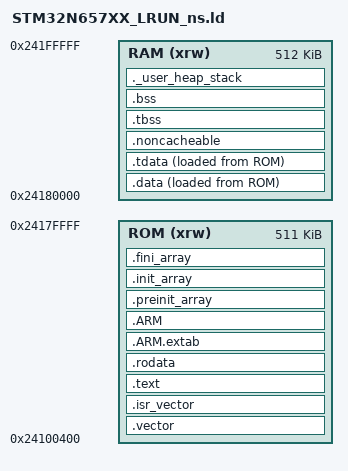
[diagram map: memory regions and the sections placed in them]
/*
 *  STM32N657XX LRUN (Non-secure) linker script for TOPPERS/ASP
 *  Based on STM32Cube STM32N657XX_LRUN_ns.ld (H747 版と同様に .vector を先頭配置)
 */

ENTRY(Reset_Handler)

software_init_hook = 0;

MEMORY
{
  ROM    (xrw)    : ORIGIN = 0x24100400,   LENGTH = 511K
  RAM    (xrw)    : ORIGIN = 0x24180000,   LENGTH = 512K
}

_estack = ORIGIN(RAM) + LENGTH(RAM);
_sstack = _estack - _Min_Stack_Size;

_Min_Heap_Size = 0x200;
_Min_Stack_Size = 0x800;

SECTIONS
{
  .vector :
  {
    . = ALIGN(4);
    KEEP(*(.vector))
    . = ALIGN(4);
  } >ROM

  .isr_vector :
  {
    . = ALIGN(4);
    KEEP(*(.isr_vector))
    . = ALIGN(4);
  } >ROM

  .text :
  {
    . = ALIGN(4);
    *(.text)
    *(.text*)
    *(.glue_7)
    *(.glue_7t)
    *(.eh_frame)
    *(.RamFunc)
    *(.RamFunc*)

    KEEP (*(.init))
    KEEP (*(.fini))

    . = ALIGN(4);
    _etext = .;
  } >ROM

  .rodata :
  {
    . = ALIGN(4);
    *(.rodata)
    *(.rodata*)
    . = ALIGN(4);
  } >ROM

  .ARM.extab   : {
    . = ALIGN(4);
    *(.ARM.extab* .gnu.linkonce.armextab.*)
    . = ALIGN(4);
  } >ROM

  .ARM : {
    . = ALIGN(4);
    __exidx_start = .;
    *(.ARM.exidx*)
    __exidx_end = .;
    . = ALIGN(4);
  } >ROM

  .preinit_array     :
  {
    . = ALIGN(4);
    PROVIDE_HIDDEN (__preinit_array_start = .);
    KEEP (*(.preinit_array*))
    PROVIDE_HIDDEN (__preinit_array_end = .);
    . = ALIGN(4);
  } >ROM

  .init_array :
  {
    . = ALIGN(4);
    PROVIDE_HIDDEN (__init_array_start = .);
    KEEP (*(SORT(.init_array.*)))
    KEEP (*(.init_array*))
    PROVIDE_HIDDEN (__init_array_end = .);
    . = ALIGN(4);
  } >ROM

  .fini_array :
  {
    . = ALIGN(4);
    PROVIDE_HIDDEN (__fini_array_start = .);
    KEEP (*(SORT(.fini_array.*)))
    KEEP (*(.fini_array*))
    PROVIDE_HIDDEN (__fini_array_end = .);
    . = ALIGN(4);
  } >ROM

  _sidata = LOADADDR(.data);

  /* start.S 用（H747 版 STM32H747XIHX_FLASH.ld と同様） */
  __idata_start = _sidata;
  __idata_end   = _sidata + SIZEOF(.data) + SIZEOF(.tdata);

  .data :
  {
    . = ALIGN(4);
    _sdata = .;
    __data_start = _sdata;
    *(.data)
    *(.data*)

    . = ALIGN(4);

  } >RAM AT> ROM

  .tdata : ALIGN(4)
  {
    *(.tdata .tdata.* .gnu.linkonce.td.*)
    . = ALIGN(4);
    _edata = .;
    PROVIDE(__data_end = .);
    PROVIDE(__tdata_end = .);
  } >RAM AT> ROM

  PROVIDE( __tdata_start = ADDR(.tdata) );
  PROVIDE( __tdata_size = __tdata_end - __tdata_start );

  PROVIDE( __data_start = ADDR(.data) );
  PROVIDE( __data_size = __data_end - __data_start );

  PROVIDE( __tdata_source = LOADADDR(.tdata) );
  PROVIDE( __tdata_source_end = LOADADDR(.tdata) + SIZEOF(.tdata) );
  PROVIDE( __tdata_source_size = __tdata_source_end - __tdata_source );

  PROVIDE( __data_source = LOADADDR(.data) );
  PROVIDE( __data_source_end = __tdata_source_end );
  PROVIDE( __data_source_size = __data_source_end - __data_source );


  .noncacheable :
  {
    . = ALIGN(8);
    __snoncacheable = .;
    KEEP(*(.noncacheable))
    . = ALIGN(8);
    __enoncacheable = .;
  } > RAM

  .tbss (NOLOAD) : ALIGN(4)
  {
    _sbss = .;
    __bss_start__ = _sbss;
    __bss_start = _sbss;
    *(.tbss .tbss.*)
    . = ALIGN(4);
    PROVIDE( __tbss_end = . );
  } >RAM

  PROVIDE( __tbss_start = ADDR(.tbss) );
  PROVIDE( __tbss_size = __tbss_end - __tbss_start );
  PROVIDE( __tbss_offset = ADDR(.tbss) - ADDR(.tdata) );

  PROVIDE( __tls_base = __tdata_start );
  PROVIDE( __tls_end = __tbss_end );
  PROVIDE( __tls_size = __tls_end - __tls_base );
  PROVIDE( __tls_align = MAX(ALIGNOF(.tdata), ALIGNOF(.tbss)) );
  PROVIDE( __tls_size_align = (__tls_size + __tls_align - 1) & ~(__tls_align - 1) );
  PROVIDE( __arm32_tls_tcb_offset = MAX(8, __tls_align) );
  PROVIDE( __arm64_tls_tcb_offset = MAX(16, __tls_align) );

  .bss (NOLOAD) : ALIGN(4)
  {
    *(.bss)
    *(.bss*)
    *(COMMON)

    . = ALIGN(4);
    _ebss = .;
    __bss_end__ = _ebss;
    __bss_end = _ebss;
  } >RAM
  PROVIDE( __non_tls_bss_start = ADDR(.bss) );

  PROVIDE( __bss_size = __bss_end - __bss_start );


  ._user_heap_stack (NOLOAD) :
  {
    . = ALIGN(8);
    PROVIDE ( end = . );
    PROVIDE ( _end = . );
    . = . + _Min_Heap_Size;
    . = . + _Min_Stack_Size;
    . = ALIGN(8);
  } >RAM

  /DISCARD/ :
  {
    libc.a:* ( * )
    libm.a:* ( * )
    libgcc.a:* ( * )
  }

  .ARM.attributes 0 : { *(.ARM.attributes) }
}
